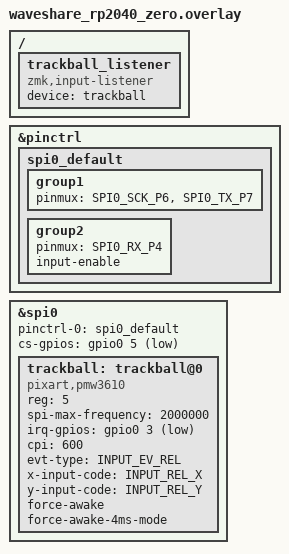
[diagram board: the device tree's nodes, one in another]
/*
 * Copyright (c) 2021 The ZMK Contributors
 *
 * SPDX-License-Identifier: MIT
 */
 
#include <zephyr/dt-bindings/input/input-event-codes.h>
#include <zephyr/dt-bindings/pinctrl/rpi-pico-rp2040-pinctrl.h>
/* {
*    chosen {
*        zephyr,console = &cdc_acm_uart;
*    };
};*/

/*&usbd {
*    cdc_acm_uart: cdc_acm_uart {
*        compatible = "zephyr,cdc-acm-uart";
*    };
};*/

&pinctrl {
    spi0_default: spi0_default {
        group1 {
            pinmux = <SPI0_SCK_P6>, <SPI0_TX_P7>;
        };
        group2 {
            pinmux = <SPI0_RX_P4>;
            input-enable;
        };
    };
};


&spi0 {
    status = "okay";
    //compatible = "raspberrypi,rp2040-spi";
    pinctrl-0 = <&spi0_default>;
    pinctrl-names = "default";
    cs-gpios = <&gpio0 5 GPIO_ACTIVE_LOW>;

    trackball: trackball@0 {
        status = "okay";
        compatible = "pixart,pmw3610";
        reg = <5>;
        spi-max-frequency = <2000000>;
        irq-gpios = <&gpio0 3 (GPIO_ACTIVE_LOW | GPIO_PULL_UP)>;
        cpi = <600>;
        // swap-xy; /* optional */
        // invert-x; /* optional */
        // invert-y; /* optional */
        evt-type = <INPUT_EV_REL>;
        x-input-code = <INPUT_REL_X>;
        y-input-code = <INPUT_REL_Y>;

        force-awake;
        /* keep the sensor awake while ZMK activity state is ACTIVE,
           fallback to normal downshift mode after ZMK goes into IDLE / SLEEP mode.
           thus, the sensor would be a `wakeup-source` */

        force-awake-4ms-mode;
        /* while force-awake is acitvated, enable this mode to force sampling per 
           4ms, where the default sampling rate is 8ms. */
        /* NOTE: apply this mode if you need 250Hz with direct USB connection. */
    };
};

/ {
  trackball_listener {
    compatible = "zmk,input-listener";
    device = <&trackball>;
  };
};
